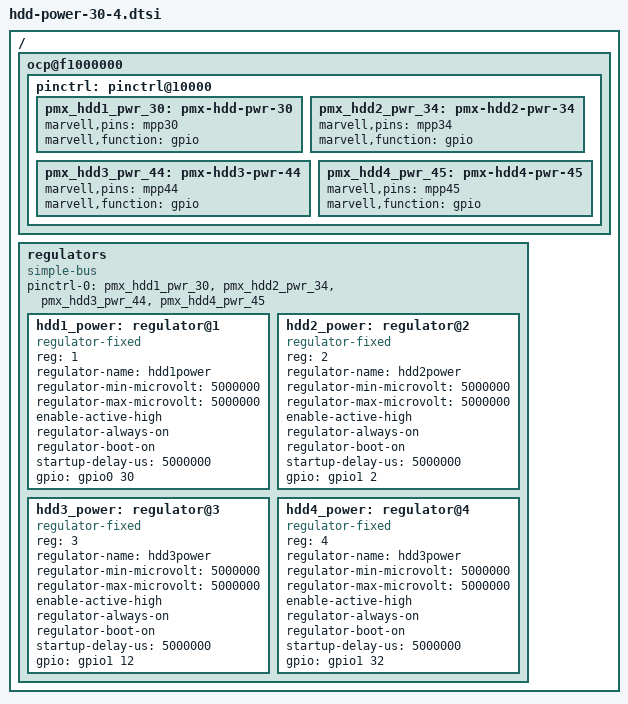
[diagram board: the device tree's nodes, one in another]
/*
 * Andrew Lunn <andrew@lunn.ch>
 *
 * This file is licensed under the terms of the GNU General Public
 * License version 2.  This program is licensed "as is" without any
 * warranty of any kind, whether express or implied.
 */

/ {
	ocp@f1000000 {
		pinctrl: pinctrl@10000 {

			pmx_hdd1_pwr_30: pmx-hdd-pwr-30 {
				marvell,pins = "mpp30";
				marvell,function = "gpio";
			};
			pmx_hdd2_pwr_34: pmx-hdd2-pwr-34 {
				marvell,pins = "mpp34";
				marvell,function = "gpio";
			};
			pmx_hdd3_pwr_44: pmx-hdd3-pwr-44 {
				marvell,pins = "mpp44";
				marvell,function = "gpio";
			};
			pmx_hdd4_pwr_45: pmx-hdd4-pwr-45 {
				marvell,pins = "mpp45";
				marvell,function = "gpio";
			};
		};
	};

	regulators {
		compatible = "simple-bus";
		#address-cells = <1>;
		#size-cells = <0>;
		pinctrl-0 = <&pmx_hdd1_pwr_30 &pmx_hdd2_pwr_34
			     &pmx_hdd3_pwr_44 &pmx_hdd4_pwr_45>;
		pinctrl-names = "default";

		hdd1_power: regulator@1 {
			compatible = "regulator-fixed";
			reg = <1>;
			regulator-name = "hdd1power";
			regulator-min-microvolt = <5000000>;
			regulator-max-microvolt = <5000000>;
			enable-active-high;
			regulator-always-on;
			regulator-boot-on;
			startup-delay-us = <5000000>;
			gpio = <&gpio0 30 GPIO_ACTIVE_HIGH>;
		};
		hdd2_power: regulator@2 {
			compatible = "regulator-fixed";
			reg = <2>;
			regulator-name = "hdd2power";
			regulator-min-microvolt = <5000000>;
			regulator-max-microvolt = <5000000>;
			enable-active-high;
			regulator-always-on;
			regulator-boot-on;
			startup-delay-us = <5000000>;
			gpio = <&gpio1 2 GPIO_ACTIVE_HIGH>;
		};
		hdd3_power: regulator@3 {
			compatible = "regulator-fixed";
			reg = <3>;
			regulator-name = "hdd3power";
			regulator-min-microvolt = <5000000>;
			regulator-max-microvolt = <5000000>;
			enable-active-high;
			regulator-always-on;
			regulator-boot-on;
			startup-delay-us = <5000000>;
			gpio = <&gpio1 12 GPIO_ACTIVE_HIGH>;
		};
		hdd4_power: regulator@4 {
			compatible = "regulator-fixed";
			reg = <4>;
			regulator-name = "hdd3power";
			regulator-min-microvolt = <5000000>;
			regulator-max-microvolt = <5000000>;
			enable-active-high;
			regulator-always-on;
			regulator-boot-on;
			startup-delay-us = <5000000>;
			gpio = <&gpio1 32 GPIO_ACTIVE_HIGH>;
		};
	};
};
